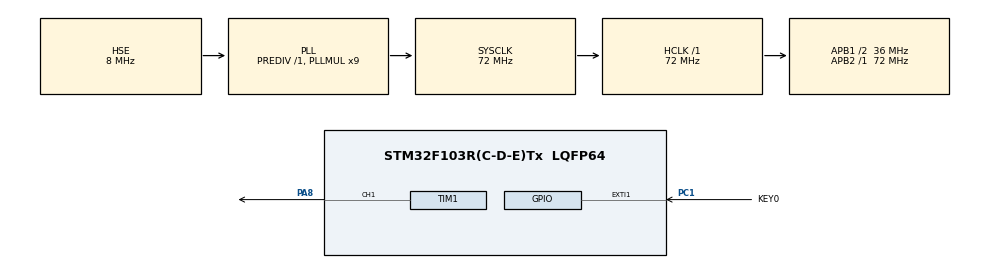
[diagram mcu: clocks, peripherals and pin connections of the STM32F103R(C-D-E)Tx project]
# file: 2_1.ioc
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Mcu.Family=STM32F1
Mcu.Name=STM32F103R(C-D-E)Tx
Mcu.Package=LQFP64
NVIC.EXTI1_IRQn=true\:1\:0\:true\:false\:true\:true\:true\:true
NVIC.PriorityGroup=NVIC_PRIORITYGROUP_4
NVIC.TIM6_IRQn=true\:2\:0\:true\:false\:true\:true\:true\:true
PA13.Mode=Serial_Wire
PA13.Signal=SYS_JTMS-SWDIO
PA14.Mode=Serial_Wire
PA14.Signal=SYS_JTCK-SWCLK
PA8.Signal=S_TIM1_CH1
PC1.GPIO_Label=KEY0
PC1.GPIO_ModeDefaultEXTI=GPIO_MODE_IT_FALLING
PC1.GPIO_PuPd=GPIO_PULLUP
PC1.Signal=GPXTI1
PD0-OSC_IN.Mode=HSE-External-Oscillator
PD0-OSC_IN.Signal=RCC_OSC_IN
PD1-OSC_OUT.Mode=HSE-External-Oscillator
PD1-OSC_OUT.Signal=RCC_OSC_OUT
ProjectManager.HeapSize=0x200
ProjectManager.StackSize=0x400
ProjectManager.TargetToolchain=MDK-ARM V5.32
RCC.AHBFreq_Value=72000000
RCC.APB1CLKDivider=RCC_HCLK_DIV2
RCC.APB1Freq_Value=36000000
RCC.APB1TimFreq_Value=72000000
RCC.APB2Freq_Value=72000000
RCC.APB2TimFreq_Value=72000000
RCC.HCLKFreq_Value=72000000
RCC.PLLMUL=RCC_PLL_MUL9
RCC.PLLSourceVirtual=RCC_PLLSOURCE_HSE
RCC.SYSCLKFreq_VALUE=72000000
RCC.SYSCLKSource=RCC_SYSCLKSOURCE_PLLCLK
RCC.USBFreq_Value=72000000
SH.S_TIM1_CH1.0=TIM1_CH1,PWM Generation1 CH1
TIM1.AutoReloadPreload=TIM_AUTORELOAD_PRELOAD_ENABLE
TIM1.Channel-PWM\ Generation1\ CH1=TIM_CHANNEL_1
TIM1.OCMode_PWM-PWM\ Generation1\ CH1=TIM_OCMODE_PWM2
TIM1.Period=20000-1
TIM1.Prescaler=72-1
TIM6.AutoReloadPreload=TIM_AUTORELOAD_PRELOAD_ENABLE
TIM6.Period=20000-1
TIM6.Prescaler=72-1
VP_TIM6_VS_ClockSourceINT.Mode=Enable_Timer
board=custom

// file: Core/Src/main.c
/* USER CODE BEGIN Header */
/**
  ******************************************************************************
  * @file           : main.c
  * @brief          : Main program body
  ******************************************************************************
  * @attention
  *
  * Copyright (c) 2025 STMicroelectronics.
  * All rights reserved.
  *
  * This software is licensed under terms that can be found in the LICENSE file
  * in the root directory of this software component.
  * If no LICENSE file comes with this software, it is provided AS-IS.
  *
  ******************************************************************************
  */
/* USER CODE END Header */
#include "main.h"
#include "tim.h"
#include "gpio.h"

/* USER CODE BEGIN PV */
uint16_t ccr = 0;
uint8_t pwm_direction = 0;
uint8_t breathing_enabled = 1;
/* USER CODE END PV */

void SystemClock_Config(void);

int main(void)
{

  /* MCU Configuration--------------------------------------------------------*/

  /* Reset of all peripherals, Initializes the Flash interface and the Systick. */
  HAL_Init();

  /* Configure the system clock */
  SystemClock_Config();

  /* Initialize all configured peripherals */
  MX_GPIO_Init();
  MX_TIM1_Init();
  MX_TIM6_Init();
  /* USER CODE BEGIN 2 */
  HAL_TIM_Base_Start_IT(&htim6);
  HAL_TIM_PWM_Start(&htim1, TIM_CHANNEL_1);
  /* USER CODE END 2 */

  /* Infinite loop */
  /* USER CODE BEGIN WHILE */
  while (1)
  {
    HAL_Delay(100);
    /* USER CODE END WHILE */

  }
}

void SystemClock_Config(void)
{
  RCC_OscInitTypeDef RCC_OscInitStruct = {0};
  RCC_ClkInitTypeDef RCC_ClkInitStruct = {0};

  /** Initializes the RCC Oscillators according to the specified parameters
  * in the RCC_OscInitTypeDef structure.
  */
  RCC_OscInitStruct.OscillatorType = RCC_OSCILLATORTYPE_HSE;
  RCC_OscInitStruct.HSEState = RCC_HSE_ON;
  RCC_OscInitStruct.HSEPredivValue = RCC_HSE_PREDIV_DIV1;
  RCC_OscInitStruct.HSIState = RCC_HSI_ON;
  RCC_OscInitStruct.PLL.PLLState = RCC_PLL_ON;
  RCC_OscInitStruct.PLL.PLLSource = RCC_PLLSOURCE_HSE;
  RCC_OscInitStruct.PLL.PLLMUL = RCC_PLL_MUL9;
  if (HAL_RCC_OscConfig(&RCC_OscInitStruct) != HAL_OK)
  {
    Error_Handler();
  }

  /** Initializes the CPU, AHB and APB buses clocks
  */
  RCC_ClkInitStruct.ClockType = RCC_CLOCKTYPE_HCLK|RCC_CLOCKTYPE_SYSCLK
                              |RCC_CLOCKTYPE_PCLK1|RCC_CLOCKTYPE_PCLK2;
  RCC_ClkInitStruct.SYSCLKSource = RCC_SYSCLKSOURCE_PLLCLK;
  RCC_ClkInitStruct.AHBCLKDivider = RCC_SYSCLK_DIV1;
  RCC_ClkInitStruct.APB1CLKDivider = RCC_HCLK_DIV2;
  RCC_ClkInitStruct.APB2CLKDivider = RCC_HCLK_DIV1;

  if (HAL_RCC_ClockConfig(&RCC_ClkInitStruct, FLASH_LATENCY_2) != HAL_OK)
  {
    Error_Handler();
  }
}

/* USER CODE BEGIN 4 */
void HAL_TIM_PeriodElapsedCallback(TIM_HandleTypeDef *htim){
    if(htim == &htim6) {
      if(breathing_enabled ==1){
        if(pwm_direction == 0) {
            // 递增
            ccr += 400;
            if(ccr >= 20000) {
                ccr = 20000;
                pwm_direction = 1;
            }
        } else {
            // 递减
            ccr -= 400;
            if(ccr <= 0) {
                ccr = 0;
                pwm_direction = 0;
            }
        }
        __HAL_TIM_SetCompare(&htim1, TIM_CHANNEL_1, ccr);
      }

    }
}

void HAL_GPIO_EXTI_Callback(uint16_t GPIO_Pin)
{
    if(GPIO_Pin == KEY0_Pin){
        HAL_Delay(50);
        if(HAL_GPIO_ReadPin(KEY0_GPIO_Port, KEY0_Pin) == GPIO_PIN_RESET){
            breathing_enabled = !breathing_enabled;
            if(!breathing_enabled){
              __HAL_TIM_SetCompare(&htim1, TIM_CHANNEL_1, 0);
            }
        }
    }
}
/* USER CODE END 4 */

void Error_Handler(void)
{
  __disable_irq();
  while (1)
  {
  }
}
